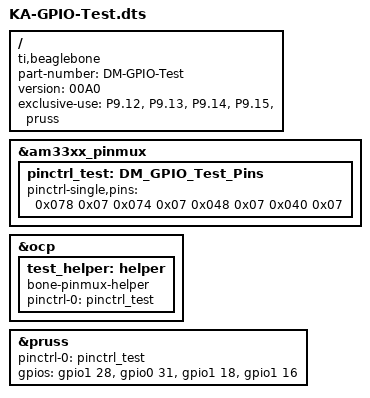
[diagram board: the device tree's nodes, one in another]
/*  
* Copyright (C) 2012 Texas Instruments Incorporated - http://www.ti.com/
*
* This program is free software; you can redistribute it and/or modify
* it under the terms of the GNU General Purpose License Version 2 as
* published by the Free Software Foundation
*
* Original from: github.com/jadonk/validation-scripts/blob/master/test-capemgr/ 
*
* Modified by Derek Molloy and Karl Anderson for the example on www.derekmolloy.ie
* that maps GPIO pins for the example
*/

/dts-v1/;
/plugin/;

/{
       compatible = "ti,beaglebone", "ti,beaglebone-black";
       part-number = "DM-GPIO-Test";
       version = "00A0";
       exclusive-use=
       "P9.12", "P9.13", "P9.14", "P9.15", "pruss";
       
       fragment@0 {
             target = <&am33xx_pinmux>;
            
             __overlay__ {
                  pinctrl_test: DM_GPIO_Test_Pins {
			pinctrl-single,pins = <

				0x078 0x07  /* P9_12 60 OUTPUT MODE7 - The LED Output */
				0x074 0x07  /* P9_13 31 OUTPUT MODE7 - LED Output 2 */
				0x048 0x07  /* P9_14 50 OUTPUT MODE7 - LED Output 3 */
                       		0x040 0x07  /* P9_15 48 OUTPUT MODE7 - LED Output 4 */
                               /* OUTPUT  GPIO(mode7) 0x07 pulldown, 0x17 pullup, 0x?f no pullup/down */

			>;
		  };
             };
       };

       fragment@1 {
		target = <&ocp>;
		__overlay__ {
			test_helper: helper {
				compatible = "bone-pinmux-helper";
				pinctrl-names = "default";
				pinctrl-0 = <&pinctrl_test>;
				status = "okay";
			};
		};
	};
	fragment@2{  
		target = <&pruss>;  
    		__overlay__ {  
      			status = "okay"; 
      			pinctrl-names = "default";
        		pinctrl-0 = <&pinctrl_test>;
        		gpios         = <
			&gpio1 28 0
			&gpio0 31 0
			&gpio1 18 0
			&gpio1 16 0
			>;
    		};  
  	};  
};
